# RP2350 register map
Vendor: Raspberry Pi; File version: 0.1
CPU: CM33 r1p0, little endian, MPU, FPU, VTOR, 4 interrupt priority bits, 54 interrupts, 8 SAU regions
Registers are 32-bit, read-write, reset 0x0 unless marked. A register's access mark holds for its fields unless they carry their own. Offsets are from the block's base; [hi:lo] are bit positions; {n}, {i} and the like mark numbered series; <NAME> marks a mode.

## WATCHDOG
Base 0x400D8000
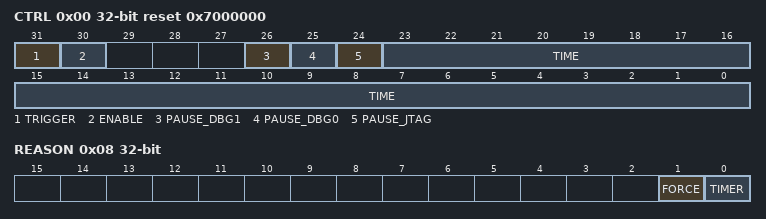
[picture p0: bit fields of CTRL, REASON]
0x00 CTRL access per field reset 0x7000000 — Watchdog control. The rst_wdsel register determines which subsystems are reset when the watchdog is triggered. The watchdog can be triggered in software.
  [31] TRIGGER rw write-clears — Trigger a watchdog reset
  [30] ENABLE rw — When not enabled the watchdog timer is paused
  [26] PAUSE_DBG1 rw — Pause the watchdog timer when processor 1 is in debug mode
  [25] PAUSE_DBG0 rw — Pause the watchdog timer when processor 0 is in debug mode
  [24] PAUSE_JTAG rw — Pause the watchdog timer when JTAG is accessing the bus fabric
  [23:0] TIME ro — Indicates the time in usec before a watchdog reset will be triggered
0x04 LOAD wo — Load the watchdog timer. The maximum setting is 0xffffff which corresponds to approximately 16 seconds.
  [23:0] LOAD
0x08 REASON ro — Logs the reason for the last reset. Both bits are zero for the case of a hardware reset. . Additionally, as of RP2350, a debugger warm reset of either core (SYSRESETREQ or hartreset) will also clear the watchdog reason register, so that software loaded under the debugger following a watchdog timeout will not continue to see the timeout condition.
  [1] FORCE, [0] TIMER
{0xC+4i} SCRATCH{i} (i=0..7) — Scratch register. Information persists through soft reset of the chip.

## BOOTRAM — Additional registers mapped adjacent to the bootram, for use by the bootrom.
Base 0x400E0000
0x800 WRITE_ONCE0 — This registers always ORs writes into its current contents. Once a bit is set, it can only be cleared by a reset.
0x804 WRITE_ONCE1 — This registers always ORs writes into its current contents. Once a bit is set, it can only be cleared by a reset.
0x808 BOOTLOCK_STAT reset 0xFF — Bootlock status register. 1=unclaimed, 0=claimed. These locks function identically to the SIO spinlocks, but are reserved for bootrom use.
  [7:0] BOOTLOCK_STAT
{0x80C+4i} BOOTLOCK{i} (i=0..7) — Read to claim and check. Write to unclaim. The value returned on successful claim is 1 << n, and on failed claim is zero.

## SHA256 — SHA-256 hash function implementation
Base 0x400F8000
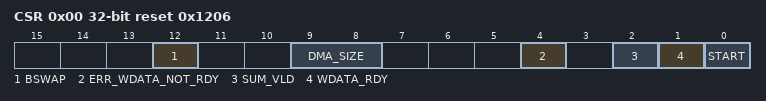
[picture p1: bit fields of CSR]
0x00 CSR access per field reset 0x1206 — Control and status register
  [12] BSWAP rw — Enable byte swapping of 32-bit values at the point they are committed to the SHA message scheduler. . This block's bus interface assembles byte/halfword data into message words in little-endian order, so that DMAing the same buffer with different transfer sizes always gives the same result on a little-endian system like RP2350. . However, when marshalling bytes into blocks, SHA expects that the first byte is the *most significant* in each message word. To resolve this, once the bus interface has accumulated 32 bits of data (either a word write, two halfword writes in little-endian order, or four byte writes in little-endian order) the final value can be byte-swapped before passing to the actual SHA core. . This feature is enabled by default because using the SHA core to checksum byte buffers is expected to be more common than having preformatted SHA message words lying around.
  [9:8] DMA_SIZE rw — Configure DREQ logic for the correct DMA data size. Must be configured before the DMA channel is triggered. . The SHA-256 core's DREQ logic requests one entire block of data at once, since there is no FIFO, and data goes straight into the core's message schedule and digest hardware. Therefore, when transferring data with DMA, CSR_DMA_SIZE must be configured in advance so that the correct number of transfers can be requested per block.
    0=8bit; 1=16bit; 2=32bit
  [4] ERR_WDATA_NOT_RDY rw write-1-clears — Set when a write occurs whilst the SHA-256 core is not ready for data (WDATA_RDY is low). Write one to clear.
  [2] SUM_VLD ro — If 1, the SHA-256 checksum presented in registers SUM0 through SUM7 is currently valid. . Goes low when WDATA is first written, then returns high once 16 words have been written and the digest of the current 512-bit block has subsequently completed.
  [1] WDATA_RDY ro — If 1, the SHA-256 core is ready to accept more data through the WDATA register. . After writing 16 words, this flag will go low for 57 cycles whilst the core completes its digest.
  [0] START rw write-clears — Write 1 to prepare the SHA-256 core for a new checksum. . The SUMx registers are initialised to the proper values (fractional bits of square roots of first 8 primes) and internal counters are cleared. This immediately forces WDATA_RDY and SUM_VLD high. . START must be written before initiating a DMA transfer to the SHA-256 core, because the core will always request 16 transfers at a time (1 512-bit block). Additionally, the DMA channel should be configured for a multiple of 16 32-bit transfers.
0x04 WDATA wo — Write data register. After pulsing START and writing 16 words of data to this register, WDATA_RDY will go low and the SHA-256 core will complete the digest of the current 512-bit block. . Software is responsible for ensuring the data is correctly padded and terminated to a whole number of 512-bit blocks. . After this, WDATA_RDY will return high, and more data can be written (if any). . This register supports word, halfword and byte writes, so that DMA from non-word-aligned buffers can be supported. The total amount of data per block remains the same (16 words, 32 halfwords or 64 bytes) and byte/halfword transfers must not be mixed within a block.
{0x8+4i} SUM{i} ro (i=0..7) — 256-bit checksum result. Contents are undefined when CSR_SUM_VLD is 0.
